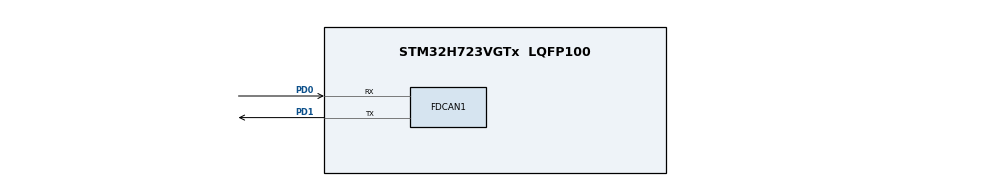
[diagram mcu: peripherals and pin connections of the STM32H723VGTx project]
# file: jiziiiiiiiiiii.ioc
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FDCAN1.NominalPrescaler=3
FDCAN1.NominalTimeSeg1=13
FDCAN1.RxFifo0ElmtsNbr=3
FDCAN1.StdFiltersNbr=1
FDCAN1.TxFifoQueueElmtsNbr=3
Mcu.Family=STM32H7
Mcu.Name=STM32H723VGTx
Mcu.Package=LQFP100
NVIC.PriorityGroup=NVIC_PRIORITYGROUP_4
PD0.Mode=FDCAN_Activate
PD0.Signal=FDCAN1_RX
PD1.Mode=FDCAN_Activate
PD1.Signal=FDCAN1_TX
PH0-OSC_IN.Mode=HSE-External-Oscillator
PH0-OSC_IN.Signal=RCC_OSC_IN
PH1-OSC_OUT.Mode=HSE-External-Oscillator
PH1-OSC_OUT.Signal=RCC_OSC_OUT
ProjectManager.HeapSize=0x200
ProjectManager.StackSize=0x400
ProjectManager.TargetToolchain=MDK-ARM V5
RCC.ADCFreq_Value=129000000
RCC.APB1Freq_Value=32000000
RCC.APB2Freq_Value=32000000
RCC.APB3Freq_Value=32000000
RCC.APB4Freq_Value=32000000
RCC.CortexFreq_Value=64000000
RCC.D1PPRE=RCC_APB3_DIV2
RCC.D2PPRE1=RCC_APB1_DIV2
RCC.D2PPRE2=RCC_APB2_DIV2
RCC.D3PPRE=RCC_APB4_DIV2
RCC.DIVM1=4
RCC.DIVN1=12
RCC.DIVQ1=4
RCC.HCLKFreq_Value=64000000
RCC.PLLFRACN=0
RCC.SYSCLKFreq_VALUE=64000000
RCC.USBFreq_Value=48000000
board=custom

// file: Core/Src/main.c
/* USER CODE BEGIN Header */
/**
  ******************************************************************************
  * @file           : main.c
  * @brief          : Main program body
  ******************************************************************************
  * @attention
  *
  * <h2><center>&copy; Copyright (c) 2026 STMicroelectronics.
  * All rights reserved.</center></h2>
  *
  * This software component is licensed by ST under BSD 3-Clause license,
  * the "License"; You may not use this file except in compliance with the
  * License. You may obtain a copy of the License at:
  *                        opensource.org/licenses/BSD-3-Clause
  *
  ******************************************************************************
  */
/* USER CODE END Header */
#include "main.h"

/* USER CODE BEGIN Includes */
#include "can.h"
/* USER CODE END Includes */

FDCAN_HandleTypeDef hfdcan1;

/* USER CODE BEGIN PV */
volatile int16_t motor_command = 2000;

volatile uint32_t can_send_count = 0;
volatile uint32_t can_receive_count = 0;
volatile CAN_Status can_last_send_status = CAN_STATUS_ERROR;

Receive_t motor1_feedback = {0};

/* USER CODE END PV */

void SystemClock_Config(void);
static void MX_GPIO_Init(void);
static void MX_FDCAN1_Init(void);

int main(void)
{

  /* MCU Configuration--------------------------------------------------------*/

  /* Reset of all peripherals, Initializes the Flash interface and the Systick. */
  HAL_Init();

  /* Configure the system clock */
  SystemClock_Config();

  /* Initialize all configured peripherals */
  MX_GPIO_Init();
  MX_FDCAN1_Init();
  /* USER CODE BEGIN 2 */
if (CAN_AppInit() != CAN_STATUS_OK)
{
    Error_Handler();
}
uint32_t last_motor_tick = 0;
  /* USER CODE END 2 */

  /* Infinite loop */
  while (1)
  {

    /* USER CODE BEGIN 3 */
	  uint8_t tx_data[8] = {0};
      uint8_t rx_data[8] = {0};
      uint32_t rx_id = 0;
      uint8_t rx_length = 0;

/* 电机 ID 1：控制值放在前两个字节，大端格式 */
tx_data[0] = (uint8_t)((uint16_t)motor_command >> 8);
tx_data[1] = (uint8_t)((uint16_t)motor_command & 0xFFU);

/* 每 1 ms 发送一次 GM6020 控制帧 */
if ((HAL_GetTick() - last_motor_tick) >= 1U)
{
    last_motor_tick = HAL_GetTick();

    can_last_send_status =
        CAN_SendStd(0x1FFU, tx_data, 8U);

    if (can_last_send_status == CAN_STATUS_OK)
    {
        can_send_count++;
    }
}

/* 读取 FIFO 中的所有反馈 */
while (CAN_ReadStd(&rx_id, rx_data, &rx_length) == CAN_STATUS_OK)
{

    if (rx_id == 0x1FFU && rx_length == 8U)
    {
     motor1_feedback.mechanical_angle =
    (uint16_t)(((uint16_t)rx_data[0] << 8) |
               (uint16_t)rx_data[1]);

motor1_feedback.speed =
    (int16_t)(((uint16_t)rx_data[2] << 8) |
              (uint16_t)rx_data[3]);

motor1_feedback.current =
    (int16_t)(((uint16_t)rx_data[4] << 8) |
              (uint16_t)rx_data[5]);

motor1_feedback.temperature = rx_data[6];

        can_receive_count++;
    }
}
  }
  /* USER CODE END 3 */
}

void SystemClock_Config(void)
{
  RCC_OscInitTypeDef RCC_OscInitStruct = {0};
  RCC_ClkInitTypeDef RCC_ClkInitStruct = {0};

  /** Supply configuration update enable
  */
  HAL_PWREx_ConfigSupply(PWR_LDO_SUPPLY);
  /** Configure the main internal regulator output voltage
  */
  __HAL_PWR_VOLTAGESCALING_CONFIG(PWR_REGULATOR_VOLTAGE_SCALE3);

  while(!__HAL_PWR_GET_FLAG(PWR_FLAG_VOSRDY)) {}
  /** Initializes the RCC Oscillators according to the specified parameters
  * in the RCC_OscInitTypeDef structure.
  */
  RCC_OscInitStruct.OscillatorType = RCC_OSCILLATORTYPE_HSI;
  RCC_OscInitStruct.HSIState = RCC_HSI_DIV1;
  RCC_OscInitStruct.HSICalibrationValue = RCC_HSICALIBRATION_DEFAULT;
  RCC_OscInitStruct.PLL.PLLState = RCC_PLL_ON;
  RCC_OscInitStruct.PLL.PLLSource = RCC_PLLSOURCE_HSI;
  RCC_OscInitStruct.PLL.PLLM = 4;
  RCC_OscInitStruct.PLL.PLLN = 12;
  RCC_OscInitStruct.PLL.PLLP = 2;
  RCC_OscInitStruct.PLL.PLLQ = 4;
  RCC_OscInitStruct.PLL.PLLR = 2;
  RCC_OscInitStruct.PLL.PLLRGE = RCC_PLL1VCIRANGE_3;
  RCC_OscInitStruct.PLL.PLLVCOSEL = RCC_PLL1VCOWIDE;
  RCC_OscInitStruct.PLL.PLLFRACN = 0;
  if (HAL_RCC_OscConfig(&RCC_OscInitStruct) != HAL_OK)
  {
    Error_Handler();
  }
  /** Initializes the CPU, AHB and APB buses clocks
  */
  RCC_ClkInitStruct.ClockType = RCC_CLOCKTYPE_HCLK|RCC_CLOCKTYPE_SYSCLK
                              |RCC_CLOCKTYPE_PCLK1|RCC_CLOCKTYPE_PCLK2
                              |RCC_CLOCKTYPE_D3PCLK1|RCC_CLOCKTYPE_D1PCLK1;
  RCC_ClkInitStruct.SYSCLKSource = RCC_SYSCLKSOURCE_HSI;
  RCC_ClkInitStruct.SYSCLKDivider = RCC_SYSCLK_DIV1;
  RCC_ClkInitStruct.AHBCLKDivider = RCC_HCLK_DIV1;
  RCC_ClkInitStruct.APB3CLKDivider = RCC_APB3_DIV2;
  RCC_ClkInitStruct.APB1CLKDivider = RCC_APB1_DIV2;
  RCC_ClkInitStruct.APB2CLKDivider = RCC_APB2_DIV2;
  RCC_ClkInitStruct.APB4CLKDivider = RCC_APB4_DIV2;

  if (HAL_RCC_ClockConfig(&RCC_ClkInitStruct, FLASH_LATENCY_1) != HAL_OK)
  {
    Error_Handler();
  }
}

static void MX_FDCAN1_Init(void)
{

  hfdcan1.Instance = FDCAN1;
  hfdcan1.Init.FrameFormat = FDCAN_FRAME_CLASSIC;
  hfdcan1.Init.Mode = FDCAN_MODE_NORMAL;
  hfdcan1.Init.AutoRetransmission = DISABLE;
  hfdcan1.Init.TransmitPause = DISABLE;
  hfdcan1.Init.ProtocolException = DISABLE;
  hfdcan1.Init.NominalPrescaler = 3;
  hfdcan1.Init.NominalSyncJumpWidth = 1;
  hfdcan1.Init.NominalTimeSeg1 = 13;
  hfdcan1.Init.NominalTimeSeg2 = 2;
  hfdcan1.Init.DataPrescaler = 1;
  hfdcan1.Init.DataSyncJumpWidth = 1;
  hfdcan1.Init.DataTimeSeg1 = 1;
  hfdcan1.Init.DataTimeSeg2 = 1;
  hfdcan1.Init.MessageRAMOffset = 0;
  hfdcan1.Init.StdFiltersNbr = 1;
  hfdcan1.Init.ExtFiltersNbr = 0;
  hfdcan1.Init.RxFifo0ElmtsNbr = 3;
  hfdcan1.Init.RxFifo0ElmtSize = FDCAN_DATA_BYTES_8;
  hfdcan1.Init.RxFifo1ElmtsNbr = 0;
  hfdcan1.Init.RxFifo1ElmtSize = FDCAN_DATA_BYTES_8;
  hfdcan1.Init.RxBuffersNbr = 0;
  hfdcan1.Init.RxBufferSize = FDCAN_DATA_BYTES_8;
  hfdcan1.Init.TxEventsNbr = 0;
  hfdcan1.Init.TxBuffersNbr = 0;
  hfdcan1.Init.TxFifoQueueElmtsNbr = 3;
  hfdcan1.Init.TxFifoQueueMode = FDCAN_TX_FIFO_OPERATION;
  hfdcan1.Init.TxElmtSize = FDCAN_DATA_BYTES_8;
  if (HAL_FDCAN_Init(&hfdcan1) != HAL_OK)
  {
    Error_Handler();
  }

}

static void MX_GPIO_Init(void)
{

  /* GPIO Ports Clock Enable */
  __HAL_RCC_GPIOH_CLK_ENABLE();
  __HAL_RCC_GPIOD_CLK_ENABLE();

}

void Error_Handler(void)
{
  __disable_irq();
  while (1)
  {
  }
}

/************************ (C) COPYRIGHT STMicroelectronics *****END OF FILE****/
